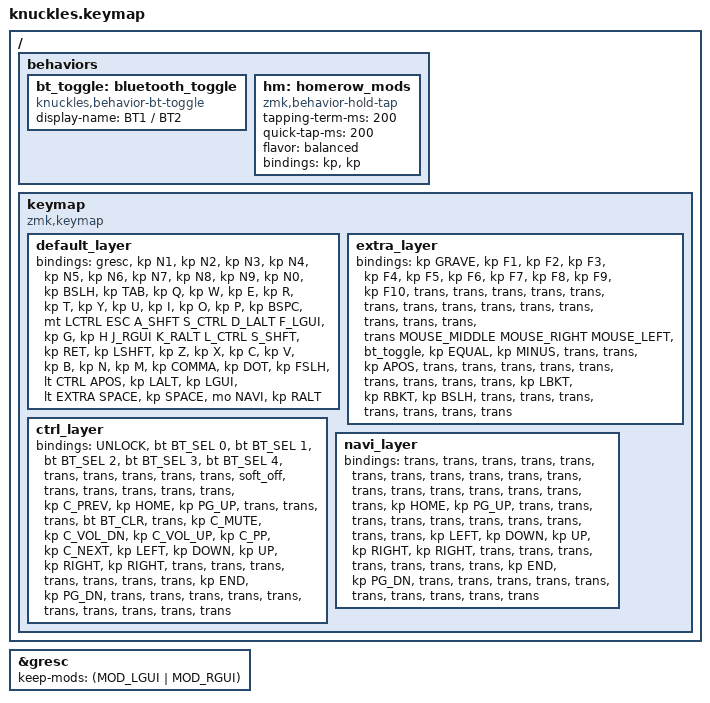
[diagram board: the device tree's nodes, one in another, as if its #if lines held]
#include <behaviors.dtsi>
#include <dt-bindings/zmk/keys.h>
#include <dt-bindings/zmk/bt.h>
#include <dt-bindings/zmk/pointing.h>

// The pointing-enabled central handles key positions from both halves.
#if defined(KNUCKLES_MOUSE_BUTTONS)
#define MOUSE_LEFT &mkp LCLK
#define MOUSE_RIGHT &mkp RCLK
#define MOUSE_MIDDLE &mkp MCLK
#else
#define MOUSE_LEFT &trans
#define MOUSE_RIGHT &trans
#define MOUSE_MIDDLE &trans
#endif

// Preserve Command when Grave/Escape morphs so macOS receives Cmd+grave.
&gresc {
    keep-mods = <(MOD_LGUI | MOD_RGUI)>;
};

#define A_SHFT &hm LSHIFT A
#define S_CTRL &hm LCTRL S
#define D_LALT &hm LALT D
#define F_LGUI &hm LWIN F
#define J_RGUI &hm RWIN J
#define K_RALT &hm RALT K
#define L_CTRL &hm RCTRL L
#define S_SHFT &hm RSHIFT SEMI

#define UNLOCK &studio_unlock
#define BT1 BT_SEL 1
#define BT2 BT_SEL 2
#define BT3 BT_SEL 3
#define BTX BT_CLR

#define DEFAULT 0
#define EXTRA   1
#define CTRL    2
#define NAVI    3

/ {
        behaviors {
            bt_toggle: bluetooth_toggle {
              compatible = "knuckles,behavior-bt-toggle";
              #binding-cells = <0>;
              display-name = "BT1 / BT2";
            };

            hm: homerow_mods {
              compatible = "zmk,behavior-hold-tap";
              #binding-cells = <2>;
              tapping-term-ms = <200>;
              quick-tap-ms = <200>;
              flavor = "balanced";
              bindings = <&kp>, <&kp>;
            };
        };
        keymap {
                compatible = "zmk,keymap";

                default_layer {
// ---------------------------------------------------------------------------------
// | Esc` |  1  |  2  |  3  |  4  |  5  |     |  6  |  7  |  8  |  9  |  0  | BKSP |
// | TAB  |  Q  |  W  |  E  |  R  |  T  |     |  Y  |  U  |  I  |  O  |  P  |  \   |
// | CTRL |  A  |  S  |  D  |  F  |  G  |     |  H  |  J  |  K  |  L  |  ;  |  ENT |
// | SHFT |  Z  |  X  |  C  |  V  |  B  |     |  N  |  M  |  ,  |  .  |  /  | APOS |
// | CTRL | ALT | GUI | SPC | SPC | SPC |     | SPC | LOW |LARW |DARW |UARW | RARW |
                        bindings = <
   &gresc        &kp N1    &kp N2    &kp N3     &kp N4     &kp N5               &kp N6     &kp N7    &kp N8     &kp N9    &kp N0    &kp BSLH
   &kp TAB       &kp Q     &kp W     &kp E      &kp R      &kp T                &kp Y      &kp U     &kp I      &kp O     &kp P     &kp BSPC
   &mt LCTRL ESC A_SHFT    S_CTRL    D_LALT     F_LGUI     &kp G                &kp H      J_RGUI    K_RALT     L_CTRL    S_SHFT    &kp RET
   &kp LSHFT     &kp Z     &kp X     &kp C      &kp V      &kp B                &kp N      &kp M     &kp COMMA  &kp DOT   &kp FSLH  &lt CTRL APOS
                                     &kp LALT   &kp LGUI   &lt EXTRA SPACE      &kp SPACE  &mo NAVI  &kp RALT
                        >;
                };

                extra_layer {
// ------------------------------------------------------------------------------------------------------------
// |  `    |   F1  |   F2  |   F3  |   F4  |   F5  |          |  F6   |  F7   |  F8   |  F9   |  F10  |       |
// |       |       |       |       |       |       |          |       |       |       |       |       |       |
// |       |       | MOUSE3| MOUSE2| MOUSE1| BT TOG|          |   =   |   -   |       |       |   '   |       |
// |       |       |       |       |       |       |          |       |       |   [   |   ]   |   /   |       |
// |       |       |       |       |       |       |          |       |       |       |       |       |       |
                        bindings = <
   &kp GRAVE &kp F1  &kp F2  &kp F3  &kp F4   &kp F5           &kp F6    &kp F7     &kp F8     &kp F9    &kp F10   &trans
   &trans    &trans  &trans  &trans  &trans   &trans           &trans    &trans     &trans     &trans    &trans    &trans
   &trans    &trans  MOUSE_MIDDLE MOUSE_RIGHT MOUSE_LEFT &bt_toggle &kp EQUAL &kp MINUS  &trans     &trans    &kp APOS  &trans
   &trans    &trans  &trans  &trans  &trans   &trans           &trans    &trans     &kp LBKT   &kp RBKT  &kp BSLH  &trans
                             &trans  &trans   &trans           &trans    &trans     &trans
                        >;
                };

                ctrl_layer {
// ------------------------------------------------------------------------------------------------------------
// |       |  BT1  |  BT2  |  BT3  |  BT4  |  BT5  |          |       |       |       |       |       |  OFF  |
// |       |       |       |       |       |       |          | HOME  | PG UP |       |       |       | BT CLR|
// |       |       |       |       |       | PREV  |          | LEFT  | DOWN  |  UP   | RIGHT | RIGHT |       |
// |       | MUTE  | VOL-  | VOL+  |PL/PAUS| NEXT  |          | END   | PG DN |       |       |       |       |
// |       |       |       |       |       |       |          |       |       |       |       |       |       |
                        bindings = <
   UNLOCK    &bt BT_SEL 0   &bt BT_SEL 1   &bt BT_SEL 2   &bt BT_SEL 3   &bt BT_SEL 4        &trans    &trans    &trans    &trans     &trans     &soft_off
   &trans    &trans         &trans         &trans         &trans         &kp C_PREV          &kp HOME  &kp PG_UP &trans    &trans     &trans     &bt BT_CLR
   &trans    &kp C_MUTE     &kp C_VOL_DN   &kp C_VOL_UP   &kp C_PP       &kp C_NEXT          &kp LEFT  &kp DOWN  &kp UP    &kp RIGHT  &kp RIGHT  &trans
   &trans    &trans         &trans         &trans         &trans         &trans              &kp END   &kp PG_DN &trans    &trans     &trans     &trans
                                           &trans         &trans         &trans              &trans    &trans    &trans
                        >;
                };

                navi_layer {
// ------------------------------------------------------------------------------------------------------------
// |       |       |       |       |       |       |          |       |       |       |       |       |       |
// |       |       |       |       |       |       |          | HOME  | PG UP |       |       |       |       |
// |       |       |       |       |       |       |          | LEFT  | DOWN  |  UP   | RIGHT | RIGHT |       |
// |       |       |       |       |       |       |          | END   | PG DN |       |       |       |       |
// |       |       |       |       |       |       |          |       |       |       |       |       |       |
                        bindings = <
   &trans    &trans         &trans         &trans         &trans         &trans              &trans    &trans    &trans    &trans     &trans     &trans
   &trans    &trans         &trans         &trans         &trans         &trans              &kp HOME  &kp PG_UP &trans    &trans     &trans     &trans
   &trans    &trans         &trans         &trans         &trans         &trans              &kp LEFT  &kp DOWN  &kp UP    &kp RIGHT  &kp RIGHT  &trans
   &trans    &trans         &trans         &trans         &trans         &trans              &kp END   &kp PG_DN &trans    &trans     &trans     &trans
                                           &trans         &trans         &trans              &trans    &trans    &trans
                        >;
                };
        };
};
